# COMPUTE_CLUSTER0_PBIST_0_PBIST register map
Vendor: Texas Instruments
Peripheral module from a debugger description file (folder am62A).
Registers are 32-bit, read-write, reset 0x0 unless marked. A register's access mark holds for its fields unless they carry their own. Offsets are as the file gives them; lines under a group give offsets from that group; [hi:lo] are bit positions; {n}, {i} and the like mark numbered series; 'fields as' and 'values as' point back to an identical list; <NAME> marks a mode.

## COMPUTE_CLUSTER0_PBIST_0_PBIST
{0x0+4i} K3_PBIST_4C28P_4BIT_WRAP_REGS_RF{i}L (i=0..15)
  [31:0] RF{i}L — Register Files / Instruction Registers RF{i} lower (RF{i}L)
{0x40+4i} K3_PBIST_4C28P_4BIT_WRAP_REGS_RF{i}U (i=0..15)
  [31:0] RF{i}U — Register Files / Instruction Registers RF{i} upper (RF{i}U)
{0x100+4i} K3_PBIST_4C28P_4BIT_WRAP_REGS_A{i} (i=0..3)
  [15:0] A{i} — Variable Address Register {i} (A{i})
{0x110+4i} K3_PBIST_4C28P_4BIT_WRAP_REGS_L{i} (i=0..3)
  [15:0] L{i} — Variable Loop Count Register {i} (L{i})
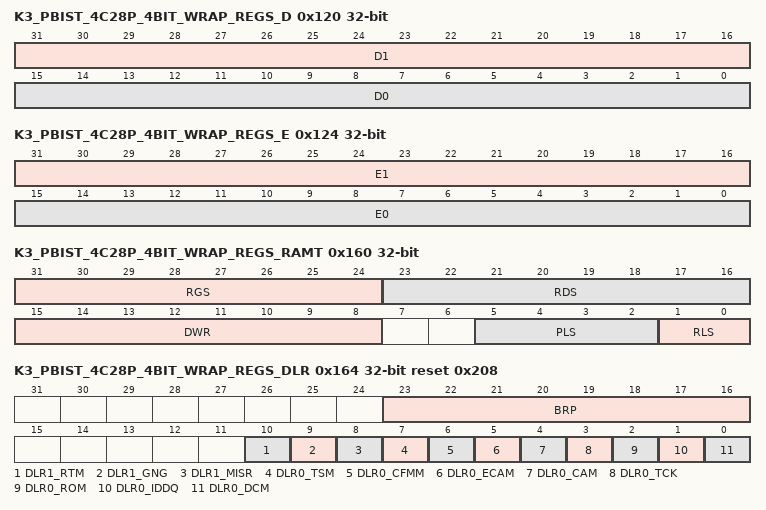
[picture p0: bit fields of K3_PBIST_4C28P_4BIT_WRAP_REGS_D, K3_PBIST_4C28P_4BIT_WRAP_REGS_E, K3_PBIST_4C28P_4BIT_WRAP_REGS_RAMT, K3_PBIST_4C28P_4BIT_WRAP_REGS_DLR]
0x120 K3_PBIST_4C28P_4BIT_WRAP_REGS_D
  [31:16] D1 — DD1 Data Register Upper 16 (D1)
  [15:0] D0 — DD0 Data Register Lower 16 (D0)
0x124 K3_PBIST_4C28P_4BIT_WRAP_REGS_E
  [31:16] E1 — EE1 Data Register Upper 16 (E1)
  [15:0] E0 — EE0 Data Register Lower 16 (E0)
{0x130+4i} K3_PBIST_4C28P_4BIT_WRAP_REGS_CA{i} (i=0..3)
  [15:0] CA{i} — Constant Address Register {i} (CA{i})
{0x140+4i} K3_PBIST_4C28P_4BIT_WRAP_REGS_CL{i} (i=0..3)
  [15:0] CL{i} — Constant Loop Count Register {i} (CL{i})
{0x150+4i} K3_PBIST_4C28P_4BIT_WRAP_REGS_I{i} (i=0..3)
  [15:0] I0 — Constant Increment Register {i} (I{i})
0x160 K3_PBIST_4C28P_4BIT_WRAP_REGS_RAMT
  [31:24] RGS — RAM Group Select RGS
  [23:16] RDS — Return Data select RDS
  [15:8] DWR — Data Width Register DWR
  [5:2] PLS — Pipeline Latency Select
  [1:0] RLS — RAM Latency Select
0x164 K3_PBIST_4C28P_4BIT_WRAP_REGS_DLR reset 0x208
  [23:16] BRP — Datalogger 2 (BRP)
  [10] DLR1_RTM — Retention testing mode
  [9] DLR1_GNG — GO / NO-GO testing mode
  [8] DLR1_MISR — MISR testing mode (mainly for ROM testing)
  [7] DLR0_TSM — Time stamp mode
  [6] DLR0_CFMM — Column Fail Masking mode
  [5] DLR0_ECAM — Emulation cache access mode
  [4] DLR0_CAM — Config access mode
  [3] DLR0_TCK — TCK Gated mode
  [2] DLR0_ROM — ROM-based testing mode
  [1] DLR0_IDDQ — IDDQ testing mode
  [0] DLR0_DCM — Distributed Compare mode
0x168 K3_PBIST_4C28P_4BIT_WRAP_REGS_CMS
  [3:0] CMS — Clock Mux Select (CMS)
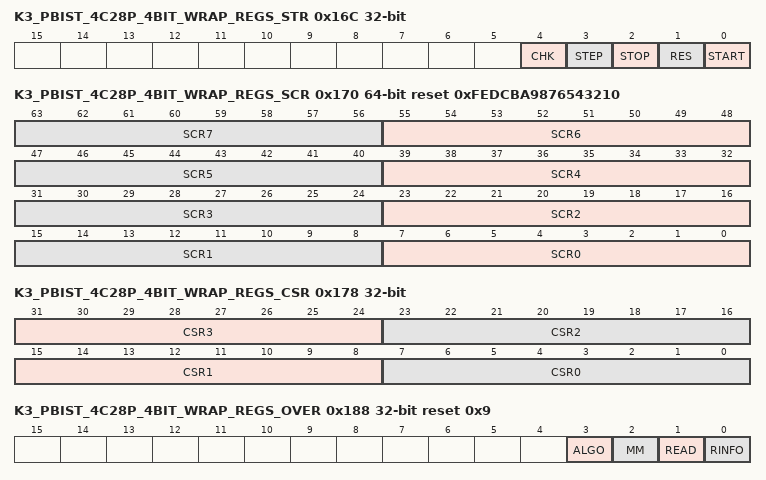
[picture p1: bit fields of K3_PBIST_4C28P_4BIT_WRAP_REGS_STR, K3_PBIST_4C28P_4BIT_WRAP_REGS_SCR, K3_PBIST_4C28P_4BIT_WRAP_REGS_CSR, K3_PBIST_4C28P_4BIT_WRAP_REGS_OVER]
0x16C K3_PBIST_4C28P_4BIT_WRAP_REGS_STR
  [4] CHK — Check MISR mode
  [3] STEP — Step / Step for emulation mode
  [2] STOP
  [1] RES — Resume / Emulation read
  [0] START — Start / Time Stamp mode restart
0x170 K3_PBIST_4C28P_4BIT_WRAP_REGS_SCR 64-bit reset 0xFEDCBA9876543210
  [8n+7:8n] SCR{n} (n=0..7) — Address Scrambling Register {n}
0x178 K3_PBIST_4C28P_4BIT_WRAP_REGS_CSR
  [31:24] CSR3 — Chip Select 3 (CSR3)
  [23:16] CSR2 — Chip Select 2 (CSR2)
  [15:8] CSR1 — Chip Select 1(CSR1)
  [7:0] CSR0 — Chip Select 0 (CSR0)
0x17C K3_PBIST_4C28P_4BIT_WRAP_REGS_FDLY reset 0x68
  [7:0] FDLY — Fail Delay (FDLY)
0x180 K3_PBIST_4C28P_4BIT_WRAP_REGS_PACT
  [0] PACT — PBIST Activate (PACT)
0x184 K3_PBIST_4C28P_4BIT_WRAP_REGS_PID
  [4:0] PID — PBIST ID
0x188 K3_PBIST_4C28P_4BIT_WRAP_REGS_OVER reset 0x9
  [3] ALGO — PBIST Override Algorithm Override
  [2] MM — PBIST Override Multiple Memory
  [1] READ — PBIST Override READ Override
  [0] RINFO — PBIST Override RINFO Override
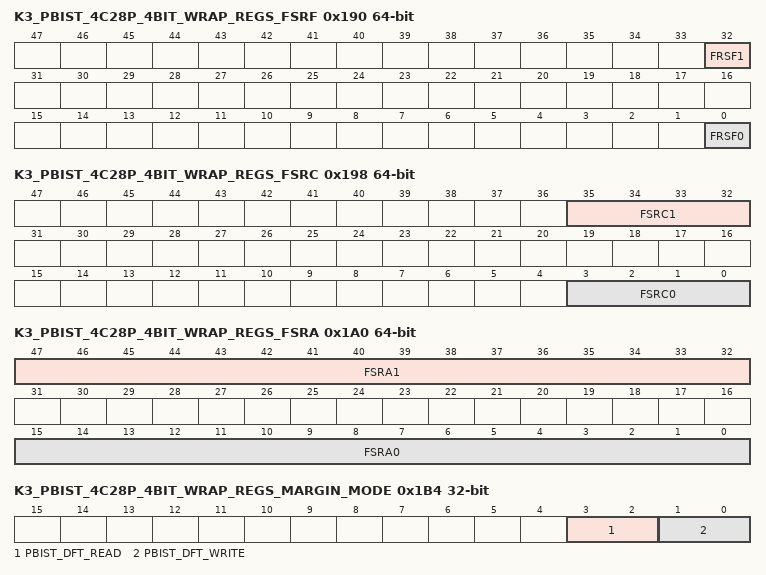
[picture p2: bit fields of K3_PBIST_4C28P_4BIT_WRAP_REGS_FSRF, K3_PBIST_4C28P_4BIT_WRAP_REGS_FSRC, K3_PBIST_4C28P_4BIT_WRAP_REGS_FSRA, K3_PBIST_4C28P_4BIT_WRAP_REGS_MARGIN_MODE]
0x190 K3_PBIST_4C28P_4BIT_WRAP_REGS_FSRF 64-bit ro
  [32] FRSF1 — Fail Status Fail - Port 1 (FSRF1)
  [0] FRSF0 — Fail Status Fail - Port 0 (FSRF0)
0x198 K3_PBIST_4C28P_4BIT_WRAP_REGS_FSRC 64-bit ro
  [35:32] FSRC1 — Fail Status Count - Port 1 (FSRC1)
  [3:0] FSRC0 — Fail Status Count - Port 0 (FSRC0)
0x1A0 K3_PBIST_4C28P_4BIT_WRAP_REGS_FSRA 64-bit ro
  [47:32] FSRA1 — Fail Status Address - Port 1 (FSRA1)
  [15:0] FSRA0 — Fail Status Address - Port 0 (FSRA0)
0x1A8 K3_PBIST_4C28P_4BIT_WRAP_REGS_FSRDL0 ro
  [31:0] FSRDL0 — Fail Status Data - Port 0 (FSRDL0)
0x1B0 K3_PBIST_4C28P_4BIT_WRAP_REGS_FSRDL1 ro
  [31:0] FSRDL1 — Fail Status Data - Port 1 (FSRDL1)
0x1B4 K3_PBIST_4C28P_4BIT_WRAP_REGS_MARGIN_MODE ro
  [3:2] PBIST_DFT_READ — pbist_dft_read[1:0]
  [1:0] PBIST_DFT_WRITE — pbist_dft_write[1:0]
0x1B8 K3_PBIST_4C28P_4BIT_WRAP_REGS_WRENZ ro
  [1:0] WRENZ — pbist_ram_wrenz[1:0]
0x1BC K3_PBIST_4C28P_4BIT_WRAP_REGS_PAGE_PGS ro
  [1:0] PGS — pbist_ram_pgs[1:0]
0x1C0 K3_PBIST_4C28P_4BIT_WRAP_REGS_ROM reset 0x3
  [1:0] ROM — ROM Mask (ROM)
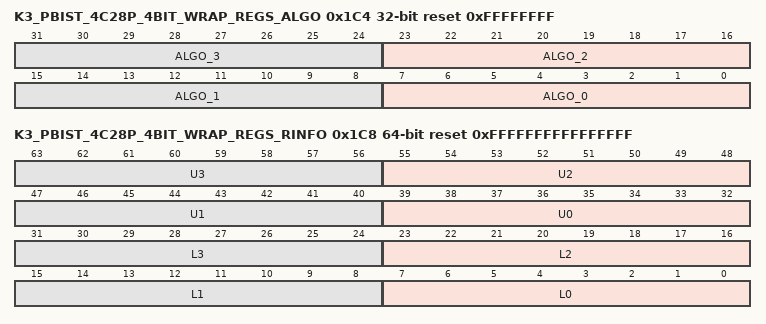
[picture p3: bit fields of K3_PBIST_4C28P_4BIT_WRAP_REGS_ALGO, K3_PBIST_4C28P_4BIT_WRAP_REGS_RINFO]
0x1C4 K3_PBIST_4C28P_4BIT_WRAP_REGS_ALGO reset 0xFFFFFFFF
  [8n+7:8n] ALGO_{n} (n=0..3) — ROM Algorithm Mask {n} (ALGO {n})
0x1C8 K3_PBIST_4C28P_4BIT_WRAP_REGS_RINFO 64-bit reset 0xFFFFFFFFFFFFFFFF
  [8n+39:8n+32] U{n} (n=0..3) — RAM Info Mask Upper {n} (RINFOU{n})
  [8n+7:8n] L{n} (n=0..3) — RAM Info Mask Lower {n} (RINFOL{n})
